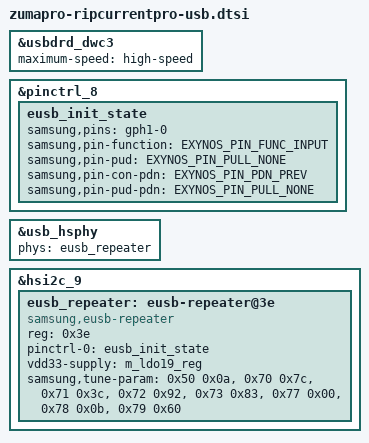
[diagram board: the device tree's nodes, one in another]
// SPDX-License-Identifier: GPL-2.0-only
/*
 * USB device tree source code for Zuma SoC
 *
 * Copyright 2023 Google LLC.
 */

&usbdrd_dwc3 {
	/* HS-only until combo-PHY SuperSpeed is brought up (see zuma-usb.dtsi) */
	maximum-speed = "high-speed";
	/*
	 * No "extcon" here on purpose: dwc3_get_extcon() runs unconditionally in
	 * dwc3 probe and -EPROBE_DEFERs (silently) until the Type-C controller's
	 * extcon is ready, which can wedge the gadget. With dr_mode="peripheral"
	 * the gadget enumerates without it. Re-add extcon/usb-role-switch when
	 * wiring up host/role switching.
	 */
};

&pinctrl_8 {
	eusb_init_state: eusb_init_state {
		samsung,pins = "gph1-0";
		samsung,pin-function = <EXYNOS_PIN_FUNC_INPUT>;
		samsung,pin-pud = <EXYNOS_PIN_PULL_NONE>;
		samsung,pin-con-pdn = <EXYNOS_PIN_PDN_PREV>;
		samsung,pin-pud-pdn = <EXYNOS_PIN_PULL_NONE>;
	};
};

/* Reference the board's eUSB2 repeater from the high-speed PHY. */
&usb_hsphy {
	phys = <&eusb_repeater>;
};

&hsi2c_9 {
	#address-cells = <1>;
	#size-cells = <0>;
	status = "okay";

	eusb_repeater: eusb-repeater@3e {
		compatible = "samsung,eusb-repeater";
		reg = <0x3e>;
		#phy-cells = <0>;
		pinctrl-names = "default";
		pinctrl-0 = <&eusb_init_state>;
		vdd33-supply = <&m_ldo19_reg>;
		/* board signal tuning, as <reg value> pairs */
		samsung,tune-param = <0x50 0x0a>,
				     <0x70 0x7c>,
				     <0x71 0x3c>,
				     <0x72 0x92>,
				     <0x73 0x83>,
				     <0x77 0x00>,
				     <0x78 0x0b>,
				     <0x79 0x60>;
		status = "okay";
	};
};
